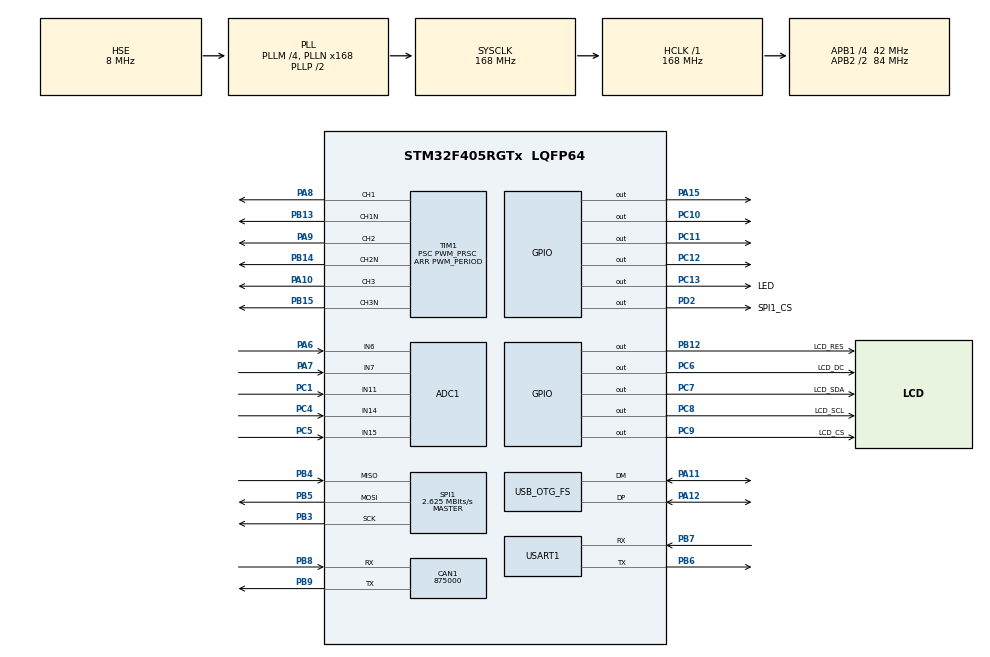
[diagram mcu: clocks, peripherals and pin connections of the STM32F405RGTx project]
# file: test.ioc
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ADC1.Channel-0\#ChannelRegularConversion=ADC_CHANNEL_11
ADC1.Channel-1\#ChannelInjectedConversion=ADC_CHANNEL_6
ADC1.Channel-2\#ChannelInjectedConversion=ADC_CHANNEL_7
ADC1.Channel-3\#ChannelInjectedConversion=ADC_CHANNEL_14
ADC1.ContinuousConvMode=ENABLE
ADC1.ExternalTrigInjecConv=ADC_EXTERNALTRIGINJECCONV_T1_CC4
ADC1.InjNumberOfConversion=3
ADC1.InjectedOffset-1\#ChannelInjectedConversion=0
ADC1.InjectedOffset-2\#ChannelInjectedConversion=0
ADC1.InjectedOffset-3\#ChannelInjectedConversion=0
ADC1.InjectedRank-1\#ChannelInjectedConversion=1
ADC1.InjectedRank-2\#ChannelInjectedConversion=2
ADC1.InjectedRank-3\#ChannelInjectedConversion=3
ADC1.NbrOfConversion=1
ADC1.NbrOfConversionFlag=1
ADC1.Rank-0\#ChannelRegularConversion=1
ADC1.SamplingTime-0\#ChannelRegularConversion=ADC_SAMPLETIME_28CYCLES
ADC1.SamplingTime-1\#ChannelInjectedConversion=ADC_SAMPLETIME_15CYCLES
ADC1.SamplingTime-2\#ChannelInjectedConversion=ADC_SAMPLETIME_15CYCLES
ADC1.SamplingTime-3\#ChannelInjectedConversion=ADC_SAMPLETIME_15CYCLES
ADC1.ScanConvMode=ENABLE
ADC1.master=1
CAN1.CalculateBaudRate=875000
CAN1.CalculateTimeBit=1142
CAN1.CalculateTimeQuantum=380.95238095238096
Dma.ADC1.0.Direction=DMA_PERIPH_TO_MEMORY
Dma.ADC1.0.FIFOMode=DMA_FIFOMODE_DISABLE
Dma.ADC1.0.Instance=DMA2_Stream0
Dma.ADC1.0.MemDataAlignment=DMA_MDATAALIGN_WORD
Dma.ADC1.0.MemInc=DMA_MINC_ENABLE
Dma.ADC1.0.Mode=DMA_CIRCULAR
Dma.ADC1.0.PeriphDataAlignment=DMA_PDATAALIGN_WORD
Dma.ADC1.0.PeriphInc=DMA_PINC_DISABLE
Dma.ADC1.0.Priority=DMA_PRIORITY_HIGH
Dma.Request0=ADC1
Mcu.Family=STM32F4
Mcu.Name=STM32F405RGTx
Mcu.Package=LQFP64
Mcu.UserConstants=CKTIM,168000000;DEADTIME_NS,200;POLE_PAIR_NUM,11;PWM_PRSC,0;PWM_FREQ,20000;PWM_PERIOD,CKTIM/(2*PWM_FREQ*(PWM_PRSC+1));DEADTIME,CKTIM/1000000/2*DEADTIME_NS/1000
NVIC.ADC_IRQn=true\:0\:0\:false\:false\:true\:true\:true\:true
NVIC.DMA2_Stream0_IRQn=true\:0\:0\:false\:false\:true\:false\:true\:true
NVIC.OTG_FS_IRQn=true\:0\:0\:false\:false\:true\:false\:true\:true
NVIC.PriorityGroup=NVIC_PRIORITYGROUP_4
NVIC.TIM2_IRQn=true\:0\:0\:false\:false\:true\:true\:true\:true
NVIC.TIM5_IRQn=true\:0\:0\:false\:false\:true\:true\:true\:true
NVIC.USART1_IRQn=true\:0\:0\:false\:false\:true\:true\:true\:true
PA10.Signal=S_TIM1_CH3
PA11.Mode=Device_Only
PA11.Signal=USB_OTG_FS_DM
PA12.Mode=Device_Only
PA12.Signal=USB_OTG_FS_DP
PA13.Mode=Serial_Wire
PA13.Signal=SYS_JTMS-SWDIO
PA14.Mode=Serial_Wire
PA14.Signal=SYS_JTCK-SWCLK
PA15.Signal=GPIO_Output
PA6.Signal=ADCx_IN6
PA7.Signal=ADCx_IN7
PA8.Signal=S_TIM1_CH1
PA9.Signal=S_TIM1_CH2
PB12.GPIO_Label=LCD_RES
PB12.GPIO_Speed=GPIO_SPEED_FREQ_VERY_HIGH
PB12.Signal=GPIO_Output
PB13.Mode=PWM Generation1 CH1 CH1N
PB13.Signal=TIM1_CH1N
PB14.Mode=PWM Generation2 CH2 CH2N
PB14.Signal=TIM1_CH2N
PB15.Mode=PWM Generation3 CH3 CH3N
PB15.Signal=TIM1_CH3N
PB3.Mode=Full_Duplex_Master
PB3.Signal=SPI1_SCK
PB4.Mode=Full_Duplex_Master
PB4.Signal=SPI1_MISO
PB5.Mode=Full_Duplex_Master
PB5.Signal=SPI1_MOSI
PB6.Mode=Asynchronous
PB6.Signal=USART1_TX
PB7.Mode=Asynchronous
PB7.Signal=USART1_RX
PB8.Mode=CAN_Activate
PB8.Signal=CAN1_RX
PB9.Mode=CAN_Activate
PB9.Signal=CAN1_TX
PC1.Signal=ADCx_IN11
PC10.Signal=GPIO_Output
PC11.Signal=GPIO_Output
PC12.Signal=GPIO_Output
PC13-ANTI_TAMP.GPIO_Label=LED
PC13-ANTI_TAMP.Signal=GPIO_Output
PC4.Signal=ADCx_IN14
PC5.Signal=ADCx_IN15
PC6.GPIO_Label=LCD_DC
PC6.GPIO_Speed=GPIO_SPEED_FREQ_VERY_HIGH
PC6.Signal=GPIO_Output
PC7.GPIO_Label=LCD_SDA
PC7.GPIO_Speed=GPIO_SPEED_FREQ_VERY_HIGH
PC7.Signal=GPIO_Output
PC8.GPIO_Label=LCD_SCL
PC8.GPIO_Speed=GPIO_SPEED_FREQ_VERY_HIGH
PC8.Signal=GPIO_Output
PC9.GPIO_Label=LCD_CS
PC9.GPIO_Speed=GPIO_SPEED_FREQ_VERY_HIGH
PC9.Signal=GPIO_Output
PD2.GPIO_Label=SPI1_CS
PD2.PinState=GPIO_PIN_SET
PD2.Signal=GPIO_Output
PH0-OSC_IN.Mode=HSE-External-Oscillator
PH0-OSC_IN.Signal=RCC_OSC_IN
PH1-OSC_OUT.Mode=HSE-External-Oscillator
PH1-OSC_OUT.Signal=RCC_OSC_OUT
ProjectManager.HeapSize=0x200
ProjectManager.StackSize=0x400
ProjectManager.TargetToolchain=MDK-ARM V5
RCC.48MHZClocksFreq_Value=48000000
RCC.AHBFreq_Value=168000000
RCC.APB1CLKDivider=RCC_HCLK_DIV4
RCC.APB1Freq_Value=42000000
RCC.APB1TimFreq_Value=84000000
RCC.APB2CLKDivider=RCC_HCLK_DIV2
RCC.APB2Freq_Value=84000000
RCC.APB2TimFreq_Value=168000000
RCC.CortexFreq_Value=168000000
RCC.HCLKFreq_Value=168000000
RCC.HSE_VALUE=8000000
RCC.HSI_VALUE=16000000
RCC.LSE_VALUE=32768
RCC.PLLM=4
RCC.PLLN=168
RCC.PLLQ=7
RCC.SYSCLKFreq_VALUE=168000000
RCC.SYSCLKSource=RCC_SYSCLKSOURCE_PLLCLK
RCC.VCOOutputFreq_Value=336000000
SH.ADCx_IN11.0=ADC1_IN11,IN11
SH.ADCx_IN14.0=ADC1_IN14,IN14
SH.ADCx_IN15.0=ADC1_IN15,IN15
SH.ADCx_IN6.0=ADC1_IN6,IN6
SH.ADCx_IN7.0=ADC1_IN7,IN7
SH.S_TIM1_CH1.0=TIM1_CH1,PWM Generation1 CH1 CH1N
SH.S_TIM1_CH2.0=TIM1_CH2,PWM Generation2 CH2 CH2N
SH.S_TIM1_CH3.0=TIM1_CH3,PWM Generation3 CH3 CH3N
SPI1.BaudRatePrescaler=SPI_BAUDRATEPRESCALER_32
SPI1.CLKPhase=SPI_PHASE_2EDGE
SPI1.CalculateBaudRate=2.625 MBits/s
SPI1.DataSize=SPI_DATASIZE_16BIT
SPI1.Direction=SPI_DIRECTION_2LINES
SPI1.Mode=SPI_MODE_MASTER
SPI1.VirtualType=VM_MASTER
TIM1.Channel-PWM\ Generation1\ CH1\ CH1N=TIM_CHANNEL_1
TIM1.Channel-PWM\ Generation2\ CH2\ CH2N=TIM_CHANNEL_2
TIM1.Channel-PWM\ Generation3\ CH3\ CH3N=TIM_CHANNEL_3
TIM1.Channel-PWM\ Generation4\ No\ Output=TIM_CHANNEL_4
TIM1.ClockDivision=TIM_CLOCKDIVISION_DIV2
TIM1.CounterMode=TIM_COUNTERMODE_CENTERALIGNED1
TIM1.DeadTime=DEADTIME
TIM1.LockLevel=TIM_LOCKLEVEL_1
TIM1.OCMode_PWM-PWM\ Generation4\ No\ Output=TIM_OCMODE_PWM2
TIM1.OffStateIDLEMode=TIM_OSSI_ENABLE
TIM1.OffStateRunMode=TIM_OSSR_ENABLE
TIM1.Period=PWM_PERIOD
TIM1.Prescaler=PWM_PRSC
TIM1.Pulse-PWM\ Generation4\ No\ Output=PWM_PERIOD-1
TIM1.RepetitionCounter=1
TIM1.TIM_MasterOutputTrigger=TIM_TRGO_OC4REF
TIM2.Prescaler=84-1
TIM5.Period=10000
TIM5.Prescaler=84-1
USART1.VirtualMode=VM_ASYNC
USB_DEVICE.CLASS_NAME_FS=CDC
USB_DEVICE.VirtualMode-CDC_FS=Cdc
USB_DEVICE.VirtualModeFS=Cdc_FS
USB_OTG_FS.VirtualMode=Device_Only
VP_TIM1_VS_ClockSourceINT.Mode=Internal
VP_TIM1_VS_no_output4.Mode=PWM Generation4 No Output
VP_TIM2_VS_ClockSourceINT.Mode=Internal
VP_TIM5_VS_ClockSourceINT.Mode=Internal
VP_USB_DEVICE_VS_USB_DEVICE_CDC_FS.Mode=CDC_FS
board=custom

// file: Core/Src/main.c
/* USER CODE BEGIN Header */
/**
  ******************************************************************************
  * @file           : main.c
  * @brief          : Main program body
  ******************************************************************************
  * @attention
  *
  * Copyright (c) 2023 STMicroelectronics.
  * All rights reserved.
  *
  * This software is licensed under terms that can be found in the LICENSE file
  * in the root directory of this software component.
  * If no LICENSE file comes with this software, it is provided AS-IS.
  *
  ******************************************************************************
  */
/* USER CODE END Header */
#include "main.h"
#include "adc.h"
#include "can.h"
#include "dma.h"
#include "spi.h"
#include "tim.h"
#include "usart.h"
#include "usb_device.h"
#include "gpio.h"

/* USER CODE BEGIN Includes */
#include "motor.h"
#include "report.h"
/* USER CODE END Includes */

/* USER CODE BEGIN PV */
extern MOTOR motor;
extern CURRENT_DQ Current_Idq;
extern VOLTAGE_DQ Voltage_DQ;
extern PID_Struct Current_IQ_Pid_2;
extern PID_Struct Speed_Pid_2;
extern float target_angle;
extern SVPWM svpwm;
/* USER CODE END PV */

void SystemClock_Config(void);

int main(void)
{

  /* MCU Configuration--------------------------------------------------------*/

  /* Reset of all peripherals, Initializes the Flash interface and the Systick. */
  HAL_Init();

  /* Configure the system clock */
  SystemClock_Config();

  /* Initialize all configured peripherals */
  MX_GPIO_Init();
  MX_DMA_Init();
  MX_SPI1_Init();
  MX_USART1_UART_Init();
  MX_ADC1_Init();
  MX_TIM1_Init();
  MX_TIM5_Init();
  MX_CAN1_Init();
  MX_USB_DEVICE_Init();
  MX_TIM2_Init();
  /* USER CODE BEGIN 2 */
	board_config();
  /* USER CODE END 2 */

  /* Infinite loop */
  while (1)
  {

    /* USER CODE BEGIN 3 */
//		HAL_GPIO_TogglePin(GPIOC,GPIO_PIN_12);
//		delay_us(100);
//		printf("%f,%f\r\n",Current_Idq.Id,Current_Idq.Iq);
//	  printf("%f,%f\r\n",Speed_Pid_2.outcome,Current_IQ_Pid_2.outcome);
//	  printf("%f,%f\r\n",Current_Idq.Id,Current_Idq.Iq);
//			printf("%f,%f,%f\r\n",motor.ia,motor.ib,motor.ic);
//		printf("%f\r\n",motor.me_angle);
//	  HAL_Delay(1);
		HAL_GPIO_TogglePin(LED_GPIO_Port,LED_Pin);
		HAL_Delay(500);

  }
  /* USER CODE END 3 */
}

void SystemClock_Config(void)
{
  RCC_OscInitTypeDef RCC_OscInitStruct = {0};
  RCC_ClkInitTypeDef RCC_ClkInitStruct = {0};

  /** Configure the main internal regulator output voltage
  */
  __HAL_RCC_PWR_CLK_ENABLE();
  __HAL_PWR_VOLTAGESCALING_CONFIG(PWR_REGULATOR_VOLTAGE_SCALE1);

  /** Initializes the RCC Oscillators according to the specified parameters
  * in the RCC_OscInitTypeDef structure.
  */
  RCC_OscInitStruct.OscillatorType = RCC_OSCILLATORTYPE_HSE;
  RCC_OscInitStruct.HSEState = RCC_HSE_ON;
  RCC_OscInitStruct.PLL.PLLState = RCC_PLL_ON;
  RCC_OscInitStruct.PLL.PLLSource = RCC_PLLSOURCE_HSE;
  RCC_OscInitStruct.PLL.PLLM = 4;
  RCC_OscInitStruct.PLL.PLLN = 168;
  RCC_OscInitStruct.PLL.PLLP = RCC_PLLP_DIV2;
  RCC_OscInitStruct.PLL.PLLQ = 7;
  if (HAL_RCC_OscConfig(&RCC_OscInitStruct) != HAL_OK)
  {
    Error_Handler();
  }

  /** Initializes the CPU, AHB and APB buses clocks
  */
  RCC_ClkInitStruct.ClockType = RCC_CLOCKTYPE_HCLK|RCC_CLOCKTYPE_SYSCLK
                              |RCC_CLOCKTYPE_PCLK1|RCC_CLOCKTYPE_PCLK2;
  RCC_ClkInitStruct.SYSCLKSource = RCC_SYSCLKSOURCE_PLLCLK;
  RCC_ClkInitStruct.AHBCLKDivider = RCC_SYSCLK_DIV1;
  RCC_ClkInitStruct.APB1CLKDivider = RCC_HCLK_DIV4;
  RCC_ClkInitStruct.APB2CLKDivider = RCC_HCLK_DIV2;

  if (HAL_RCC_ClockConfig(&RCC_ClkInitStruct, FLASH_LATENCY_5) != HAL_OK)
  {
    Error_Handler();
  }
}

void Error_Handler(void)
{
  __disable_irq();
  while (1)
  {
  }
}
